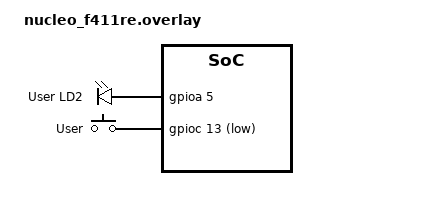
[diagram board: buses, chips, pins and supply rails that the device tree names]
/ {
  leds {
    compatible = "gpio-leds";
    blinking_led: blinking_led {
      gpios = <&gpioa 5 GPIO_ACTIVE_HIGH>;
      label = "User LD2";
    };
  };

  buttons {
    compatible = "gpio-keys";
    button: button {
      gpios = <&gpioc 13 GPIO_ACTIVE_LOW>;
      label = "User";
    };
  };
};
